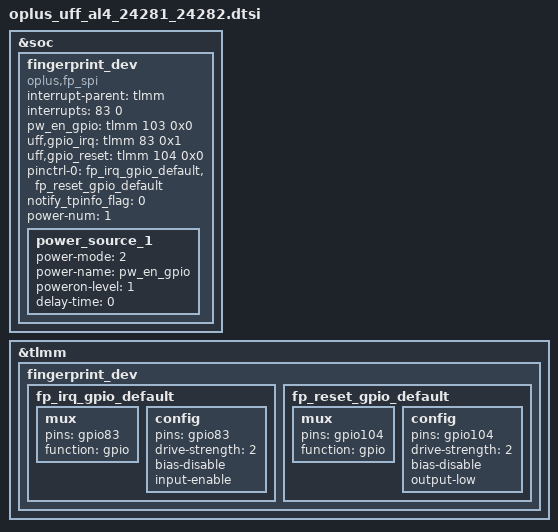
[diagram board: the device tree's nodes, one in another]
&soc {
	fingerprint_dev {
		status = "ok";
		compatible = "oplus,fp_spi";
		interrupt-parent = <&tlmm>;
		interrupts = <83 0>;
		//power-mode = <1> ; /*0: power mode not set, 1: ldo power, 2: gpio power, 3: auto power */
		//ldo-supply = <&L14B>;
		//ldo-config = <3008000 3008000 150000>;
		pw_en_gpio = <&tlmm 103 0x0>;
		uff,gpio_irq = <&tlmm 83 0x1>;
		uff,gpio_reset = <&tlmm 104 0x0>;
		pinctrl-names = "default";
		pinctrl-0 = <&fp_irq_gpio_default>,<&fp_reset_gpio_default>;
		notify_tpinfo_flag = <0>;
		power-num = <1>;
		power_source_1 {
			power-mode = <2>;
			power-name = "pw_en_gpio";
			poweron-level = <1>;
			delay-time = <0>;
		};
	};
};

&tlmm {
	fingerprint_dev{
		fp_irq_gpio_default: fp_irq_gpio_default {
			mux {
				pins = "gpio83";
				function = "gpio";
			};
			config {
				pins = "gpio83";
				drive-strength = <2>;
				bias-disable;
				input-enable;
			};
		};

		fp_reset_gpio_default: fp_reset_gpio_default {
			mux {
				pins = "gpio104";
				function = "gpio";
			};
			config {
				pins = "gpio104";
				drive-strength = <2>;
				bias-disable;
				output-low;
			};
		};
	};
};
